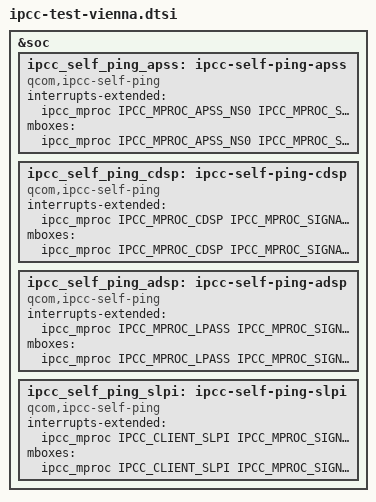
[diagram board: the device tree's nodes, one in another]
// SPDX-License-Identifier: BSD-3-Clause
/*
 * Copyright (c) 2024 Qualcomm Innovation Center, Inc. All rights reserved.
 */

#include <dt-bindings/soc/qcom,ipcc.h>
#include <dt-bindings/mailbox/qcom-ipcc-vienna.h>

&soc {
	ipcc_self_ping_apss: ipcc-self-ping-apss {
		compatible = "qcom,ipcc-self-ping";
		interrupts-extended = <&ipcc_mproc IPCC_MPROC_APSS_NS0
			IPCC_MPROC_SIGNAL_SMP2P IRQ_TYPE_LEVEL_HIGH>;
		mboxes = <&ipcc_mproc IPCC_MPROC_APSS_NS0 IPCC_MPROC_SIGNAL_SMP2P>;
	};

	ipcc_self_ping_cdsp: ipcc-self-ping-cdsp {
		compatible = "qcom,ipcc-self-ping";
		interrupts-extended = <&ipcc_mproc IPCC_MPROC_CDSP
				IPCC_MPROC_SIGNAL_PING IRQ_TYPE_LEVEL_HIGH>;
		mboxes = <&ipcc_mproc IPCC_MPROC_CDSP IPCC_MPROC_SIGNAL_PING>;
	};

	ipcc_self_ping_adsp: ipcc-self-ping-adsp {
		compatible = "qcom,ipcc-self-ping";
		interrupts-extended = <&ipcc_mproc IPCC_MPROC_LPASS
				IPCC_MPROC_SIGNAL_PING IRQ_TYPE_LEVEL_HIGH>;
		mboxes = <&ipcc_mproc IPCC_MPROC_LPASS IPCC_MPROC_SIGNAL_PING>;
	};

	ipcc_self_ping_slpi: ipcc-self-ping-slpi {
		compatible = "qcom,ipcc-self-ping";
		interrupts-extended = <&ipcc_mproc IPCC_CLIENT_SLPI
				IPCC_MPROC_SIGNAL_PING IRQ_TYPE_LEVEL_HIGH>;
		mboxes = <&ipcc_mproc IPCC_CLIENT_SLPI IPCC_MPROC_SIGNAL_PING>;
	};
};
